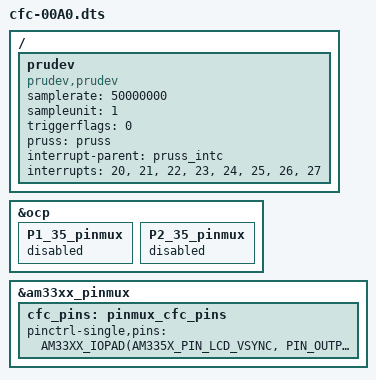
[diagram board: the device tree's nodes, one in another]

/dts-v1/;
/plugin/;

#include <dt-bindings/gpio/gpio.h>
#include <dt-bindings/pinctrl/am33xx.h>

/ {
  // disable the P1_28_pinmux as we define our own
  fragment@0 {
    target = <&ocp>;
    __overlay__ {
      P1_35_pinmux { status = "disabled"; };	/* gpio0_13.uart1_rtsn */
      P2_35_pinmux { status = "disabled"; };	/* gpio0_13.uart1_rtsn */
    };
  };

  fragment@1 {
    target-path="/";
    __overlay__ {
      /* Add default settings for the LA core */
      prudev {
        compatible = "prudev,prudev";
        samplerate = <50000000>;	/* All (100 / n) MHz sample rates, = 1,2,... */ // TODO remove
        sampleunit = <1>;		/* 0:16-bit samples, 1:8-bit samples */
        triggerflags = <0>; 		/* 0:one-shot, 1:continuous */

        pruss = <&pruss>;
        interrupt-parent = <&pruss_intc>;
        interrupts = <20>, <21>, <22>, <23>, <24>, <25>, <26>, <27>;
        interrupt-names = "20", "21", "22", "23", "24", "25", "26", "27";
      };
    };
  };

  // overlay the pinmux with the pin modes we need
  fragment@2 {
    target = <&am33xx_pinmux>;
    __overlay__ {
      cfc_pins: pinmux_cfc_pins {
            pinctrl-single,pins = <
              AM33XX_IOPAD(AM335X_PIN_LCD_VSYNC, PIN_OUTPUT_PULLDOWN | INPUT_EN | MUX_MODE7)
              AM33XX_IOPAD(AM335X_PIN_LCD_PCLK, PIN_OUTPUT_PULLDOWN | INPUT_EN | MUX_MODE7)
              >;
      };
    };
  };
};
